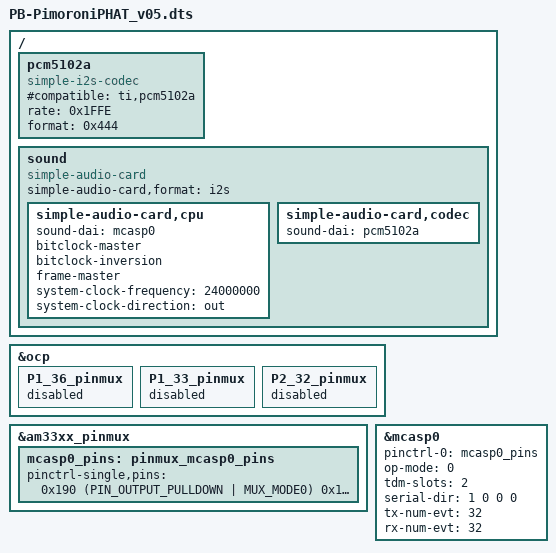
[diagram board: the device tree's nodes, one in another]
/*
*Copyright <2018> <Logan Baldridge>
*
*Permission is hereby granted, free of charge, to any person obtaining a copy of 
*this software and associated documentation files (the "Software"), to deal in 
*the Software without restriction, including without limitation the rights to 
*use, copy, modify, merge, publish, distribute, sublicense, and/or sell copies 
*of the Software, and to permit persons to whom the Software is furnished to do 
*so, subject to the following conditions:
*
*The above copyright notice and this permission notice shall be included in 
*all copies or substantial portions of the Software.
*
*THE SOFTWARE IS PROVIDED "AS IS", WITHOUT WARRANTY OF ANY KIND, EXPRESS OR 
*IMPLIED, INCLUDING BUT NOT LIMITED TO THE WARRANTIES OF MERCHANTABILITY, 
*FITNESS FOR A PARTICULAR PURPOSE AND NONINFRINGEMENT. IN NO EVENT SHALL THE 
*AUTHORS OR COPYRIGHT HOLDERS BE LIABLE FOR ANY CLAIM, DAMAGES OR OTHER 
*LIABILITY, WHETHER IN AN ACTION OF CONTRACT, TORT OR OTHERWISE, ARISING FROM, 
*OUT OF OR IN CONNECTION WITH THE SOFTWARE OR THE USE OR OTHER DEALINGS 
*IN THE SOFTWARE.
*
*/
/dts-v1/;
/plugin/;

#include <dt-bindings/gpio/gpio.h>
#include <dt-bindings/pinctrl/am33xx.h>

/ {

	/*
	 * Free up the pins used by the cape from the pinmux helpers.
	 */
	fragment@0 {
		target = <&ocp>;
		__overlay__ {
			P1_36_pinmux { status = "disabled"; };	/* mcasp0_aclkx */
			P1_33_pinmux { status = "disabled"; };	/* mcasp0_fsx */
			P2_32_pinmux { status = "disabled"; };	/* mcasp0_axr0 */
		};
	};

	fragment@1 {
		target = <&am33xx_pinmux>;
		__overlay__ {
			mcasp0_pins: pinmux_mcasp0_pins {
				pinctrl-single,pins = <
					0x190 (PIN_OUTPUT_PULLDOWN | MUX_MODE0) /* mcasp0_aclkx */
					0x194 (PIN_OUTPUT_PULLDOWN | MUX_MODE0) /* mcasp0_fsx*/
					0x198 (PIN_OUTPUT_PULLDOWN | MUX_MODE0) /* mcasp0_axr0 */
				>;
			};
		};
	};

	fragment@2 {
		target-path="/";
		__overlay__ {
			pcm5102a: pcm5102a{
				#sound-dai-cells = <0>;   
				#compatible = "ti,pcm5102a";
				compatible = "simple-i2s-codec";
				# rate = <SNDRV_PCM_RATE_8000_192000>;
				rate = <0x1FFE>;
				# format = <SNDRV_PCM_FMTBIT_S16_LE | SNDRV_PCM_FMTBIT_S24_LE | SNDRV_PCM_FMTBIT_S32_LE>;
                # From https://elixir.bootlin.com/linux/v4.2/source/include/sound/pcm.h#L144
                #define SNDRV_PCM_FMTBIT_S16_LE		_SNDRV_PCM_FMTBIT(S16_LE)
                #define SNDRV_PCM_FMTBIT_S24_LE		_SNDRV_PCM_FMTBIT(S24_LE)
                #define SNDRV_PCM_FMTBIT_S32_LE		_SNDRV_PCM_FMTBIT(S32_LE)
                #define _SNDRV_PCM_FMTBIT(fmt)		(1ULL << (__force int)SNDRV_PCM_FORMAT_##fmt)
                # From https://elixir.bootlin.com/linux/v4.7/source/include/uapi/sound/asound.h#L190
                #define	SNDRV_PCM_FORMAT_S16_LE	((__force snd_pcm_format_t) 2)
                #define	SNDRV_PCM_FORMAT_S24_LE	((__force snd_pcm_format_t) 6) /* low three bytes */
                #define	SNDRV_PCM_FORMAT_S32_LE	((__force snd_pcm_format_t) 10)
				format = <0x444>;
			};
            
			sound {
				compatible = "simple-audio-card";
				simple-audio-card,format = "i2s";
				simple-audio-card,cpu {
					sound-dai = <&mcasp0>;
					bitclock-master;
					bitclock-inversion;
					frame-master;
					system-clock-frequency = <24000000>;
					system-clock-direction = "out";
				};
                
				simple-audio-card,codec {
					sound-dai = <&pcm5102a>;      
				};
			};
		};
	};

	fragment@3 {
		target = <&mcasp0>;
		__overlay__ {
			#sound-dai-cells = <0>;       
			pinctrl-names = "default";
			pinctrl-0 = <&mcasp0_pins>;
			status = "okay";
			op-mode = <0>;          /* MCASP_IIS_MODE */
			tdm-slots = <2>;
			/* 16 serializer */
			serial-dir = <  /* 0: INACTIVE, 1: TX, 2: RX */
				1 0 0 0
			>;
			tx-num-evt = <32>;
			rx-num-evt = <32>;
		};
	};
};
